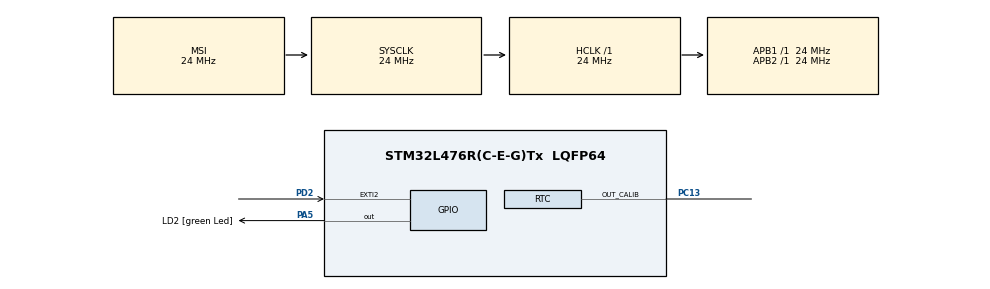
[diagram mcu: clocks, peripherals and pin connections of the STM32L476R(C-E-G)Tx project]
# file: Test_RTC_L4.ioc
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Mcu.Family=STM32L4
Mcu.Name=STM32L476R(C-E-G)Tx
Mcu.Package=LQFP64
NVIC.EXTI2_IRQn=true\:0\:0\:false\:false\:true\:true\:true
NVIC.LPTIM1_IRQn=true\:0\:0\:false\:false\:true\:true\:true
NVIC.PriorityGroup=NVIC_PRIORITYGROUP_4
NVIC.RTC_WKUP_IRQn=true\:0\:0\:false\:false\:true\:true\:true
PA13\ (JTMS-SWDIO).GPIO_Label=TMS
PA13\ (JTMS-SWDIO).Mode=Serial_Wire
PA13\ (JTMS-SWDIO).Signal=SYS_JTMS-SWDIO
PA14\ (JTCK-SWCLK).GPIO_Label=TCK
PA14\ (JTCK-SWCLK).Mode=Serial_Wire
PA14\ (JTCK-SWCLK).Signal=SYS_JTCK-SWCLK
PA5.GPIO_Label=LD2 [green Led]
PA5.GPIO_ModeDefaultOutputPP=GPIO_MODE_OUTPUT_PP
PA5.GPIO_PuPd=GPIO_NOPULL
PA5.GPIO_Speed=GPIO_SPEED_FREQ_LOW
PA5.Signal=GPIO_Output
PB3\ (JTDO-TRACESWO).GPIO_Label=SWO
PB3\ (JTDO-TRACESWO).Signal=SYS_JTDO-SWO
PC13.Mode=Calibration_1Hz
PC13.Signal=RTC_OUT_CALIB
PC14-OSC32_IN\ (PC14).Mode=LSE-External-Oscillator
PC14-OSC32_IN\ (PC14).Signal=RCC_OSC32_IN
PC15-OSC32_OUT\ (PC15).Mode=LSE-External-Oscillator
PC15-OSC32_OUT\ (PC15).Signal=RCC_OSC32_OUT
PD2.Signal=GPXTI2
PH0-OSC_IN\ (PH0).Mode=HSE-External-Oscillator
PH0-OSC_IN\ (PH0).Signal=RCC_OSC_IN
PH1-OSC_OUT\ (PH1).Mode=HSE-External-Oscillator
PH1-OSC_OUT\ (PH1).Signal=RCC_OSC_OUT
ProjectManager.HeapSize=0x200
ProjectManager.StackSize=0x400
ProjectManager.TargetToolchain=TrueSTUDIO
RCC.ADCFreq_Value=32000000
RCC.AHBFreq_Value=24000000
RCC.APB1Freq_Value=24000000
RCC.APB1TimFreq_Value=24000000
RCC.APB2Freq_Value=24000000
RCC.APB2TimFreq_Value=24000000
RCC.CortexFreq_Value=24000000
RCC.HCLKFreq_Value=24000000
RCC.HSE_VALUE=8000000
RCC.HSI_VALUE=16000000
RCC.LPTIM1CLockSelection=RCC_LPTIM1CLKSOURCE_LSE
RCC.MSIClockRange=RCC_MSIRANGE_9
RCC.MSI_VALUE=24000000
RCC.PLLN=9
RCC.PLLR=RCC_PLLR_DIV6
RCC.PLLSourceVirtual=RCC_PLLSOURCE_HSE
RCC.PREFETCH_ENABLE=1
RCC.RTCClockSelection=RCC_RTCCLKSOURCE_LSE
RCC.SYSCLKFreq_VALUE=24000000
RCC.USBFreq_Value=32000000
RCC.VCOOutputFreq_Value=72000000
RTC.WakeUpClock-WakeUp=RTC_WAKEUPCLOCK_CK_SPRE_16BITS
RTC.WakeUpCounter-WakeUp=100
VP_LPTIM1_VS_LPTIM_counterModeInternalClock.Mode=Counts__internal_clock_event_00
VP_RTC_VS_RTC_Activate.Mode=RTC_Enabled
VP_RTC_VS_RTC_WakeUp_intern.Mode=WakeUp
board=NUCLEO-L476RG

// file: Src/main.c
/* USER CODE BEGIN Header */
/**
  ******************************************************************************
  * @file           : main.c
  * @brief          : Main program body
  ******************************************************************************
  * @attention
  *
  * <h2><center>&copy; Copyright (c) 2020 STMicroelectronics.
  * All rights reserved.</center></h2>
  *
  * This software component is licensed by ST under BSD 3-Clause license,
  * the "License"; You may not use this file except in compliance with the
  * License. You may obtain a copy of the License at:
  *                        opensource.org/licenses/BSD-3-Clause
  *
  ******************************************************************************
  */
/* USER CODE END Header */

#include "main.h"

LPTIM_HandleTypeDef hlptim1;

RTC_HandleTypeDef hrtc;

/* USER CODE BEGIN PV */
uint8_t count;
uint32_t LSE_CLK_PULSE_TOTAL;
uint32_t flag;
uint32_t clock_sync_flag;
uint32_t prev_ss,curr_ss;
/* USER CODE END PV */

void SystemClock_Config(void);
static void MX_GPIO_Init(void);
static void MX_RTC_Init(void);
static void MX_LPTIM1_Init(void);
/* USER CODE BEGIN PFP */
void EXTI_ENABLE_IT(IRQn_Type IRQn);
/* USER CODE END PFP */

/* USER CODE BEGIN 0 */
void calibrate_RTC(void)
{
	uint32_t expected_pulses = 1048576;
	int32_t smooth_calib_plus_pulses = RTC_SMOOTHCALIB_PLUSPULSES_RESET;
	int32_t smooth_calib_minus_pulses_value = 0x0;
	if(LSE_CLK_PULSE_TOTAL > expected_pulses)
	{
		smooth_calib_minus_pulses_value = (uint32_t)(LSE_CLK_PULSE_TOTAL - expected_pulses);
	} else
	{
		smooth_calib_plus_pulses = RTC_SMOOTHCALIB_PLUSPULSES_SET;
		smooth_calib_minus_pulses_value = (uint32_t)(((uint32_t) 0x000001FF) - (expected_pulses - LSE_CLK_PULSE_TOTAL));
	}
    if (smooth_calib_minus_pulses_value > ((uint32_t) 0x000001FF))
    {
      smooth_calib_minus_pulses_value = (uint32_t) (((uint32_t) 0x000001FF));
    }
	HAL_RTCEx_SetSmoothCalib(&hrtc,RTC_SMOOTHCALIB_PERIOD_32SEC,smooth_calib_plus_pulses,smooth_calib_minus_pulses_value);
}
void EXTI_ENABLE_IT(IRQn_Type IRQn)
{
	 HAL_NVIC_ClearPendingIRQ(IRQn);
	 HAL_NVIC_EnableIRQ(IRQn);
}
extern void HAL_GPIO_EXTI_Callback(uint16_t GPIO_Pin)
{
	if(clock_sync_flag)
	{

			//set RTC clock counter to 0;
			RTC_TimeTypeDef time;
			RTC_DateTypeDef date;
			HAL_RTC_GetTime(&hrtc,&time,RTC_FORMAT_BIN);
			count++;
			prev_ss = curr_ss;
			curr_ss = time.SubSeconds;
			if(count == 2)
			{
				//calculate difference in subseconds

				uint16_t time_diff = curr_ss - prev_ss;
				if(time_diff < 0)
				{
					HAL_RTCEx_SetSynchroShift(&hrtc,RTC_SHIFTADD1S_SET,-time_diff);
				} else if(time_diff > 0)
				{
					HAL_RTCEx_SetSynchroShift(&hrtc,RTC_SHIFTADD1S_RESET,time_diff);
				}else if (time_diff == 0)
				{
					clock_sync_flag = 0;
					count = 0;
				}
			}

	}else{

		if(count >= 32)
		{
			//stop
			flag = 1;
			LSE_CLK_PULSE_TOTAL += HAL_LPTIM_ReadCounter(&hlptim1);
			HAL_LPTIM_Counter_Stop(&hlptim1);
			HAL_NVIC_ClearPendingIRQ(EXTI2_IRQn);
			HAL_NVIC_DisableIRQ(EXTI2_IRQn);
			__HAL_GPIO_EXTI_CLEAR_IT(EXTI_LINE_2);

		} else
		{
			//increment counter
			//save Counter from LSE
			count++;
			HAL_GPIO_TogglePin(LD2_GPIO_Port,LD2_Pin);
		}
	}

}
/* USER CODE END 0 */

int main(void)
{

  /* MCU Configuration--------------------------------------------------------*/

  /* Reset of all peripherals, Initializes the Flash interface and the Systick. */
  HAL_Init();

  /* Configure the system clock */
  SystemClock_Config();

  /* Initialize all configured peripherals */
  MX_GPIO_Init();
  MX_RTC_Init();
  MX_LPTIM1_Init();
  /* USER CODE BEGIN 2 */
  //synchronise clock to incoming signal
  clock_sync_flag = SET;
  EXTI_ENABLE_IT(EXTI2_IRQn);
  //wait for synchronization
  while(clock_sync_flag == SET)
  {

  }
//  HAL_GPIO_WritePin(LD2_GPIO_Port,LD2_Pin, SET);
//  HAL_Delay(500);
  /* USER CODE END 2 */

  /* Infinite loop */
  /* USER CODE BEGIN WHILE */
//  if (HAL_RTCEx_SetWakeUpTimer_IT(&hrtc, 100, RTC_WAKEUPCLOCK_CK_SPRE_16BITS) != HAL_OK)
//   {
//     Error_Handler();
//   }
//  	  int i = 0;
//  	  HAL_PWREx_EnterSHUTDOWNMode();
//begin IC Timer on LSE
 __HAL_LPTIM_ENABLE_IT(&hlptim1,LPTIM_IT_ARRM);
HAL_LPTIM_Counter_Start(&hlptim1,0xFFFF);

//begin Rising Trigger detection on GPIO EXTI

//c

//calculate periods
  while (1)
  {
    /* USER CODE END WHILE */

    /* USER CODE BEGIN 3 */
	  if(flag)
	  {
		 //run callibration procedure
		  calibrate_RTC();
		  flag = 0;
	  }
	  __NOP();
  }
  /* USER CODE END 3 */
}

void SystemClock_Config(void)
{
  RCC_OscInitTypeDef RCC_OscInitStruct = {0};
  RCC_ClkInitTypeDef RCC_ClkInitStruct = {0};
  RCC_PeriphCLKInitTypeDef PeriphClkInit = {0};

  /** Configure LSE Drive Capability
  */
  HAL_PWR_EnableBkUpAccess();
  __HAL_RCC_LSEDRIVE_CONFIG(RCC_LSEDRIVE_LOW);
  /** Initializes the CPU, AHB and APB busses clocks
  */
  RCC_OscInitStruct.OscillatorType = RCC_OSCILLATORTYPE_LSE|RCC_OSCILLATORTYPE_MSI;
  RCC_OscInitStruct.LSEState = RCC_LSE_ON;
  RCC_OscInitStruct.MSIState = RCC_MSI_ON;
  RCC_OscInitStruct.MSICalibrationValue = 0;
  RCC_OscInitStruct.MSIClockRange = RCC_MSIRANGE_9;
  RCC_OscInitStruct.PLL.PLLState = RCC_PLL_NONE;
  if (HAL_RCC_OscConfig(&RCC_OscInitStruct) != HAL_OK)
  {
    Error_Handler();
  }
  /** Initializes the CPU, AHB and APB busses clocks
  */
  RCC_ClkInitStruct.ClockType = RCC_CLOCKTYPE_HCLK|RCC_CLOCKTYPE_SYSCLK
                              |RCC_CLOCKTYPE_PCLK1|RCC_CLOCKTYPE_PCLK2;
  RCC_ClkInitStruct.SYSCLKSource = RCC_SYSCLKSOURCE_MSI;
  RCC_ClkInitStruct.AHBCLKDivider = RCC_SYSCLK_DIV1;
  RCC_ClkInitStruct.APB1CLKDivider = RCC_HCLK_DIV1;
  RCC_ClkInitStruct.APB2CLKDivider = RCC_HCLK_DIV1;

  if (HAL_RCC_ClockConfig(&RCC_ClkInitStruct, FLASH_LATENCY_1) != HAL_OK)
  {
    Error_Handler();
  }
  PeriphClkInit.PeriphClockSelection = RCC_PERIPHCLK_RTC|RCC_PERIPHCLK_LPTIM1;
  PeriphClkInit.Lptim1ClockSelection = RCC_LPTIM1CLKSOURCE_LSE;
  PeriphClkInit.RTCClockSelection = RCC_RTCCLKSOURCE_LSE;
  if (HAL_RCCEx_PeriphCLKConfig(&PeriphClkInit) != HAL_OK)
  {
    Error_Handler();
  }
  /** Configure the main internal regulator output voltage
  */
  if (HAL_PWREx_ControlVoltageScaling(PWR_REGULATOR_VOLTAGE_SCALE1) != HAL_OK)
  {
    Error_Handler();
  }
  /** Enable MSI Auto calibration
  */
  HAL_RCCEx_EnableMSIPLLMode();
}

static void MX_LPTIM1_Init(void)
{

  hlptim1.Instance = LPTIM1;
  hlptim1.Init.Clock.Source = LPTIM_CLOCKSOURCE_APBCLOCK_LPOSC;
  hlptim1.Init.Clock.Prescaler = LPTIM_PRESCALER_DIV1;
  hlptim1.Init.Trigger.Source = LPTIM_TRIGSOURCE_SOFTWARE;
  hlptim1.Init.OutputPolarity = LPTIM_OUTPUTPOLARITY_HIGH;
  hlptim1.Init.UpdateMode = LPTIM_UPDATE_IMMEDIATE;
  hlptim1.Init.CounterSource = LPTIM_COUNTERSOURCE_INTERNAL;
  hlptim1.Init.Input1Source = LPTIM_INPUT1SOURCE_GPIO;
  hlptim1.Init.Input2Source = LPTIM_INPUT2SOURCE_GPIO;
  if (HAL_LPTIM_Init(&hlptim1) != HAL_OK)
  {
    Error_Handler();
  }

}

static void MX_RTC_Init(void)
{

  /** Initialize RTC Only
  */
  hrtc.Instance = RTC;
  hrtc.Init.HourFormat = RTC_HOURFORMAT_24;
  hrtc.Init.AsynchPrediv = 127;
  hrtc.Init.SynchPrediv = 255;
  hrtc.Init.OutPut = RTC_OUTPUT_DISABLE;
  hrtc.Init.OutPutRemap = RTC_OUTPUT_REMAP_NONE;
  hrtc.Init.OutPutPolarity = RTC_OUTPUT_POLARITY_HIGH;
  hrtc.Init.OutPutType = RTC_OUTPUT_TYPE_OPENDRAIN;
  if (HAL_RTC_Init(&hrtc) != HAL_OK)
  {
    Error_Handler();
  }
  /** Enable the WakeUp
  */
  if (HAL_RTCEx_SetWakeUpTimer_IT(&hrtc, 100, RTC_WAKEUPCLOCK_CK_SPRE_16BITS) != HAL_OK)
  {
    Error_Handler();
  }
  /** Enable Calibration
  */
  if (HAL_RTCEx_SetCalibrationOutPut(&hrtc, RTC_CALIBOUTPUT_1HZ) != HAL_OK)
  {
    Error_Handler();
  }

}

static void MX_GPIO_Init(void)
{
  GPIO_InitTypeDef GPIO_InitStruct = {0};

  /* GPIO Ports Clock Enable */
  __HAL_RCC_GPIOC_CLK_ENABLE();
  __HAL_RCC_GPIOH_CLK_ENABLE();
  __HAL_RCC_GPIOA_CLK_ENABLE();
  __HAL_RCC_GPIOD_CLK_ENABLE();
  __HAL_RCC_GPIOB_CLK_ENABLE();

  /*Configure GPIO pin Output Level */
  HAL_GPIO_WritePin(LD2_GPIO_Port, LD2_Pin, GPIO_PIN_RESET);

  /*Configure GPIO pin : LD2_Pin */
  GPIO_InitStruct.Pin = LD2_Pin;
  GPIO_InitStruct.Mode = GPIO_MODE_OUTPUT_PP;
  GPIO_InitStruct.Pull = GPIO_NOPULL;
  GPIO_InitStruct.Speed = GPIO_SPEED_FREQ_LOW;
  HAL_GPIO_Init(LD2_GPIO_Port, &GPIO_InitStruct);

  /*Configure GPIO pin : PD2 */
  GPIO_InitStruct.Pin = GPIO_PIN_2;
  GPIO_InitStruct.Mode = GPIO_MODE_IT_RISING;
  GPIO_InitStruct.Pull = GPIO_NOPULL;
  HAL_GPIO_Init(GPIOD, &GPIO_InitStruct);

  /* EXTI interrupt init*/
  HAL_NVIC_SetPriority(EXTI2_IRQn, 0, 0);

}

/* USER CODE BEGIN 4 */
extern void HAL_LPTIM_AutoReloadMatchCallback(LPTIM_HandleTypeDef* hlptim)
{
	if(__HAL_LPTIM_GET_IT_SOURCE(hlptim,LPTIM_IT_ARRM))
	{
		//Add Counter val to Total pulses
		LSE_CLK_PULSE_TOTAL += 0xFFFF;
		//clear flag
		__HAL_LPTIM_CLEAR_FLAG(hlptim,LPTIM_FLAG_ARRM);
	}
}
/* USER CODE END 4 */

void Error_Handler(void)
{
}

/************************ (C) COPYRIGHT STMicroelectronics *****END OF FILE****/
